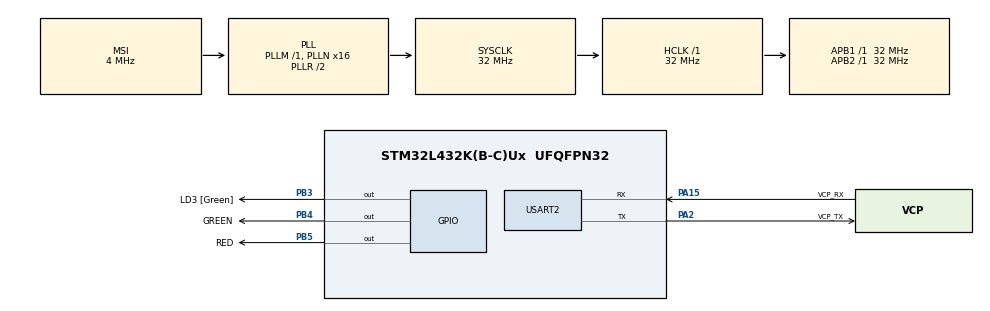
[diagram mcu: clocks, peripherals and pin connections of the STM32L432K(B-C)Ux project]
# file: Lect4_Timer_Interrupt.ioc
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Mcu.Family=STM32L4
Mcu.Name=STM32L432K(B-C)Ux
Mcu.Package=UFQFPN32
NVIC.PriorityGroup=NVIC_PRIORITYGROUP_4
NVIC.TIM1_UP_TIM16_IRQn=true\:0\:0\:false\:false\:true\:true\:true
NVIC.TIM7_IRQn=true\:0\:0\:false\:false\:true\:true\:true
PA0.GPIO_Label=MCO [High speed clock in]
PA0.Mode=HSE-External-Clock-Source-for-LittleOrca
PA0.Signal=RCC_CK_IN
PA13\ (JTMS-SWDIO).GPIO_Label=SWDIO
PA13\ (JTMS-SWDIO).Mode=Serial_Wire
PA13\ (JTMS-SWDIO).Signal=SYS_JTMS-SWDIO
PA14\ (JTCK-SWCLK).GPIO_Label=SWCLK
PA14\ (JTCK-SWCLK).Mode=Serial_Wire
PA14\ (JTCK-SWCLK).Signal=SYS_JTCK-SWCLK
PA15\ (JTDI).GPIO_Label=VCP_RX
PA15\ (JTDI).Mode=Asynchronous
PA15\ (JTDI).Signal=USART2_RX
PA2.GPIO_Label=VCP_TX
PA2.Mode=Asynchronous
PA2.Signal=USART2_TX
PB3\ (JTDO-TRACESWO).GPIO_Label=LD3 [Green]
PB3\ (JTDO-TRACESWO).Signal=GPIO_Output
PB4\ (NJTRST).GPIO_Label=GREEN
PB4\ (NJTRST).Signal=GPIO_Output
PB5.GPIO_Label=RED
PB5.Signal=GPIO_Output
PC14-OSC32_IN\ (PC14).Mode=LSE-External-Oscillator
PC14-OSC32_IN\ (PC14).Signal=RCC_OSC32_IN
PC15-OSC32_OUT\ (PC15).Mode=LSE-External-Oscillator
PC15-OSC32_OUT\ (PC15).Signal=RCC_OSC32_OUT
ProjectManager.HeapSize=0x200
ProjectManager.StackSize=0x400
ProjectManager.TargetToolchain=STM32CubeIDE
RCC.AHBFreq_Value=32000000
RCC.APB1Freq_Value=32000000
RCC.APB1TimFreq_Value=32000000
RCC.APB2Freq_Value=32000000
RCC.APB2TimFreq_Value=32000000
RCC.CortexFreq_Value=32000000
RCC.HCLKFreq_Value=32000000
RCC.HSE_VALUE=8000000
RCC.HSI16_VALUE=16000000
RCC.HSI48_VALUE=48000000
RCC.HSI_VALUE=16000000
RCC.MSI_VALUE=4000000
RCC.PLLMUL=RCC_PLLMUL_4
RCC.PLLN=16
RCC.SYSCLKFreq_VALUE=32000000
RCC.SYSCLKSource=RCC_SYSCLKSOURCE_PLLCLK
RCC.VCOOutputFreq_Value=64000000
TIM16.Period=9999
TIM16.Prescaler=3199
TIM7.Period=19999
TIM7.Prescaler=3199
USART2.VirtualMode-Asynchronous=VM_ASYNC
VP_TIM16_VS_ClockSourceINT.Mode=Enable_Timer
VP_TIM7_VS_ClockSourceINT.Mode=Enable_Timer
board=NUCLEO-L432KC

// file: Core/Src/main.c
/* USER CODE BEGIN Header */
/**
  ******************************************************************************
  * @file           : main.c
  * @brief          : Main program body
  ******************************************************************************
  * @attention
  *
  * <h2><center>&copy; Copyright (c) 2020 STMicroelectronics.
  * All rights reserved.</center></h2>
  *
  * This software component is licensed by ST under BSD 3-Clause license,
  * the "License"; You may not use this file except in compliance with the
  * License. You may obtain a copy of the License at:
  *                        opensource.org/licenses/BSD-3-Clause
  *
  ******************************************************************************
  */
/* USER CODE END Header */
#include "main.h"

TIM_HandleTypeDef htim7;
TIM_HandleTypeDef htim16;

UART_HandleTypeDef huart2;

void SystemClock_Config(void);
static void MX_GPIO_Init(void);
static void MX_USART2_UART_Init(void);
static void MX_TIM16_Init(void);
static void MX_TIM7_Init(void);

int main(void)
{

  /* MCU Configuration--------------------------------------------------------*/

  /* Reset of all peripherals, Initializes the Flash interface and the Systick. */
  HAL_Init();

  /* Configure the system clock */
  SystemClock_Config();

  /* Initialize all configured peripherals */
  MX_GPIO_Init();
  MX_USART2_UART_Init();
  MX_TIM16_Init();
  MX_TIM7_Init();
  /* USER CODE BEGIN 2 */
  HAL_TIM_Base_Start_IT(&htim16);
  HAL_TIM_Base_Start_IT(&htim7);

  /* USER CODE END 2 */

  /* Infinite loop */
  /* USER CODE BEGIN WHILE */
  HAL_GPIO_WritePin(GPIOB, RED_Pin|GREEN_Pin, GPIO_PIN_SET);
  while (1)
  {
    /* USER CODE END WHILE */

  }
}

void SystemClock_Config(void)
{
  RCC_OscInitTypeDef RCC_OscInitStruct = {0};
  RCC_ClkInitTypeDef RCC_ClkInitStruct = {0};
  RCC_PeriphCLKInitTypeDef PeriphClkInit = {0};

  /** Configure LSE Drive Capability
  */
  HAL_PWR_EnableBkUpAccess();
  __HAL_RCC_LSEDRIVE_CONFIG(RCC_LSEDRIVE_LOW);
  /** Initializes the RCC Oscillators according to the specified parameters
  * in the RCC_OscInitTypeDef structure.
  */
  RCC_OscInitStruct.OscillatorType = RCC_OSCILLATORTYPE_LSE|RCC_OSCILLATORTYPE_MSI;
  RCC_OscInitStruct.LSEState = RCC_LSE_ON;
  RCC_OscInitStruct.MSIState = RCC_MSI_ON;
  RCC_OscInitStruct.MSICalibrationValue = 0;
  RCC_OscInitStruct.MSIClockRange = RCC_MSIRANGE_6;
  RCC_OscInitStruct.PLL.PLLState = RCC_PLL_ON;
  RCC_OscInitStruct.PLL.PLLSource = RCC_PLLSOURCE_MSI;
  RCC_OscInitStruct.PLL.PLLM = 1;
  RCC_OscInitStruct.PLL.PLLN = 16;
  RCC_OscInitStruct.PLL.PLLP = RCC_PLLP_DIV7;
  RCC_OscInitStruct.PLL.PLLQ = RCC_PLLQ_DIV2;
  RCC_OscInitStruct.PLL.PLLR = RCC_PLLR_DIV2;
  if (HAL_RCC_OscConfig(&RCC_OscInitStruct) != HAL_OK)
  {
    Error_Handler();
  }
  /** Initializes the CPU, AHB and APB buses clocks
  */
  RCC_ClkInitStruct.ClockType = RCC_CLOCKTYPE_HCLK|RCC_CLOCKTYPE_SYSCLK
                              |RCC_CLOCKTYPE_PCLK1|RCC_CLOCKTYPE_PCLK2;
  RCC_ClkInitStruct.SYSCLKSource = RCC_SYSCLKSOURCE_PLLCLK;
  RCC_ClkInitStruct.AHBCLKDivider = RCC_SYSCLK_DIV1;
  RCC_ClkInitStruct.APB1CLKDivider = RCC_HCLK_DIV1;
  RCC_ClkInitStruct.APB2CLKDivider = RCC_HCLK_DIV1;

  if (HAL_RCC_ClockConfig(&RCC_ClkInitStruct, FLASH_LATENCY_1) != HAL_OK)
  {
    Error_Handler();
  }
  PeriphClkInit.PeriphClockSelection = RCC_PERIPHCLK_USART2;
  PeriphClkInit.Usart2ClockSelection = RCC_USART2CLKSOURCE_PCLK1;
  if (HAL_RCCEx_PeriphCLKConfig(&PeriphClkInit) != HAL_OK)
  {
    Error_Handler();
  }
  /** Configure the main internal regulator output voltage
  */
  if (HAL_PWREx_ControlVoltageScaling(PWR_REGULATOR_VOLTAGE_SCALE1) != HAL_OK)
  {
    Error_Handler();
  }
  /** Enable MSI Auto calibration
  */
  HAL_RCCEx_EnableMSIPLLMode();
}

static void MX_TIM7_Init(void)
{

  TIM_MasterConfigTypeDef sMasterConfig = {0};

  /* USER CODE BEGIN TIM7_Init 1 */
  //  period = (3199+1)*(19999+1)/32 MHz = 2 seconds
  /* USER CODE END TIM7_Init 1 */
  htim7.Instance = TIM7;
  htim7.Init.Prescaler = 3199;
  htim7.Init.CounterMode = TIM_COUNTERMODE_UP;
  htim7.Init.Period = 19999;
  htim7.Init.AutoReloadPreload = TIM_AUTORELOAD_PRELOAD_DISABLE;
  if (HAL_TIM_Base_Init(&htim7) != HAL_OK)
  {
    Error_Handler();
  }
  sMasterConfig.MasterOutputTrigger = TIM_TRGO_RESET;
  sMasterConfig.MasterSlaveMode = TIM_MASTERSLAVEMODE_DISABLE;
  if (HAL_TIMEx_MasterConfigSynchronization(&htim7, &sMasterConfig) != HAL_OK)
  {
    Error_Handler();
  }

}

static void MX_TIM16_Init(void)
{

  /* USER CODE BEGIN TIM16_Init 1 */
	//  period = (3199+1)*(9999+1)/32 MHz = 1 second
  /* USER CODE END TIM16_Init 1 */
  htim16.Instance = TIM16;
  htim16.Init.Prescaler = 3199;
  htim16.Init.CounterMode = TIM_COUNTERMODE_UP;
  htim16.Init.Period = 9999;
  htim16.Init.ClockDivision = TIM_CLOCKDIVISION_DIV1;
  htim16.Init.RepetitionCounter = 0;
  htim16.Init.AutoReloadPreload = TIM_AUTORELOAD_PRELOAD_DISABLE;
  if (HAL_TIM_Base_Init(&htim16) != HAL_OK)
  {
    Error_Handler();
  }

}

static void MX_USART2_UART_Init(void)
{

  huart2.Instance = USART2;
  huart2.Init.BaudRate = 115200;
  huart2.Init.WordLength = UART_WORDLENGTH_8B;
  huart2.Init.StopBits = UART_STOPBITS_1;
  huart2.Init.Parity = UART_PARITY_NONE;
  huart2.Init.Mode = UART_MODE_TX_RX;
  huart2.Init.HwFlowCtl = UART_HWCONTROL_NONE;
  huart2.Init.OverSampling = UART_OVERSAMPLING_16;
  huart2.Init.OneBitSampling = UART_ONE_BIT_SAMPLE_DISABLE;
  huart2.AdvancedInit.AdvFeatureInit = UART_ADVFEATURE_NO_INIT;
  if (HAL_UART_Init(&huart2) != HAL_OK)
  {
    Error_Handler();
  }

}

static void MX_GPIO_Init(void)
{
  GPIO_InitTypeDef GPIO_InitStruct = {0};

  /* GPIO Ports Clock Enable */
  __HAL_RCC_GPIOC_CLK_ENABLE();
  __HAL_RCC_GPIOA_CLK_ENABLE();
  __HAL_RCC_GPIOB_CLK_ENABLE();

  /*Configure GPIO pin Output Level */
  HAL_GPIO_WritePin(GPIOB, LD3_Pin|GREEN_Pin|RED_Pin, GPIO_PIN_RESET);

  /*Configure GPIO pins : LD3_Pin GREEN_Pin RED_Pin */
  GPIO_InitStruct.Pin = LD3_Pin|GREEN_Pin|RED_Pin;
  GPIO_InitStruct.Mode = GPIO_MODE_OUTPUT_PP;
  GPIO_InitStruct.Pull = GPIO_NOPULL;
  GPIO_InitStruct.Speed = GPIO_SPEED_FREQ_LOW;
  HAL_GPIO_Init(GPIOB, &GPIO_InitStruct);

}

/* USER CODE BEGIN 4 */
void HAL_TIM_PeriodElapsedCallback(TIM_HandleTypeDef *htim)
{
	if(htim==&htim16)
	{
		HAL_GPIO_TogglePin(GPIOB, RED_Pin);
	}
	if(htim==&htim7)
	{
		HAL_GPIO_TogglePin(GPIOB, GREEN_Pin);
	}
}

/* USER CODE END 4 */

void Error_Handler(void)
{
}

/************************ (C) COPYRIGHT STMicroelectronics *****END OF FILE****/
